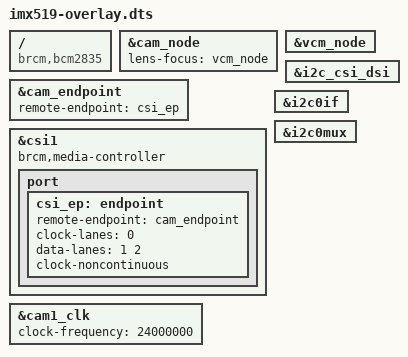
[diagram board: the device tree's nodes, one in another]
// SPDX-License-Identifier: GPL-2.0-only
// Definitions for imx519 camera module on VC I2C bus
/dts-v1/;
/plugin/;

#include <dt-bindings/gpio/gpio.h>

/{
	compatible = "brcm,bcm2835";

	i2c_frag: fragment@0 {
		target = <&i2c_csi_dsi>;
		__overlay__ {
			#address-cells = <1>;
			#size-cells = <0>;
			status = "okay";

			#include "imx519.dtsi"
		};
	};

	csi_frag: fragment@1 {
		target = <&csi1>;
		csi: __overlay__ {
			status = "okay";
			brcm,media-controller;

			port{
				csi_ep: endpoint{
					remote-endpoint = <&cam_endpoint>;
					clock-lanes = <0>;
					data-lanes = <1 2>;
					clock-noncontinuous;
				};
			};
		};
	};

	fragment@2 {
		target = <&i2c0if>;
		__overlay__ {
			status = "okay";
		};
	};

	clk_frag: fragment@3 {
		target = <&cam1_clk>;
		__overlay__ {
			clock-frequency = <24000000>;
			status = "okay";
		};
	};

	fragment@4 {
		target = <&i2c0mux>;
		__overlay__ {
			status = "okay";
		};
	};

	fragment@5 {
		target = <&cam_node>;
		__overlay__ {
			lens-focus = <&vcm_node>;
		};
	};

	__overrides__ {
		rotation = <&cam_node>,"rotation:0";
		orientation = <&cam_node>,"orientation:0";
		media-controller = <&csi>,"brcm,media-controller?";
		cam0 = <&i2c_frag>, "target:0=",<&i2c_csi_dsi0>,
		       <&csi_frag>, "target:0=",<&csi0>,
		       <&clk_frag>, "target:0=",<&cam0_clk>,
		       <&cam_node>, "clocks:0=",<&cam0_clk>,
		       <&cam_node>, "VANA-supply:0=",<&cam0_reg>,
		       <&vcm_node>, "vdd-supply:0=",<&cam0_reg>;
		vcm = <&vcm_node>, "status",
		      <0>, "=5";
	};
};

&cam_node {
	status = "okay";
};

&cam_endpoint {
	remote-endpoint = <&csi_ep>;
};

&vcm_node {
	status = "okay";
};
